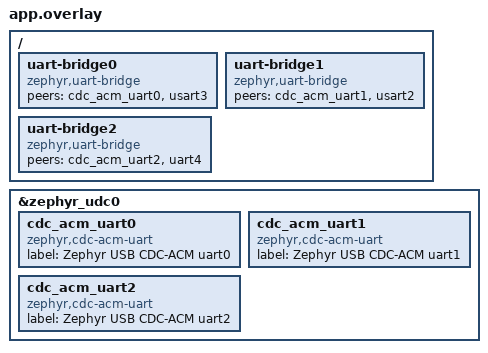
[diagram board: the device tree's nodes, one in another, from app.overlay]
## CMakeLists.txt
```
# SPDX-License-Identifier: Apache-2.0

cmake_minimum_required(VERSION 3.20.0)
find_package(Zephyr REQUIRED HINTS $ENV{ZEPHYR_BASE})
project(USB_UART_HUB)

include(${ZEPHYR_BASE}/samples/subsys/usb/common/common.cmake)
FILE(GLOB app_sources src/*.c)
target_sources(app PRIVATE ${app_sources})
```

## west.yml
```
manifest:
  remotes:
    - name: zephyrproject-rtos
      url-base: https://github.com/zephyrproject-rtos

  projects:
    - name: zephyr
      remote: zephyrproject-rtos
      revision: v4.3.0
      import:
        # Use the allow-list to keep it slim!
        name-allowlist:
          - cmsis
          - cmsis_6
          - hal_stm32

  self:
    path: USB_UART_HUB  # This matches your repo name
```

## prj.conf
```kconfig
CONFIG_UART_CONSOLE=y

CONFIG_USB_DEVICE_STACK_NEXT=y

CONFIG_SERIAL=y
CONFIG_UART_LINE_CTRL=y
CONFIG_UART_USE_RUNTIME_CONFIGURE=y
CONFIG_USBD_CDC_ACM_CLASS=y
CONFIG_CDC_ACM_SERIAL_INITIALIZE_AT_BOOT=n
CONFIG_UDC_BUF_POOL_SIZE=8192

CONFIG_SAMPLE_USBD_PID=0x0001
CONFIG_SAMPLE_USBD_PRODUCT="USBD CDC ACM bridge sample"

CONFIG_LOG=y
CONFIG_LOG_BUFFER_SIZE=8192

CONFIG_NET_BUF=y
# CONFIG_UART_ASYNC_API=y
CONFIG_UART_BRIDGE=y
```

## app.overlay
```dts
/*
 * Copyright 2025 Google LLC
 *
 * SPDX-License-Identifier: Apache-2.0
 */

/ {
	uart-bridge0 {
		compatible = "zephyr,uart-bridge";
		peers = <&cdc_acm_uart0 &usart3>;
	};

	uart-bridge1 {
		compatible = "zephyr,uart-bridge";
		peers = <&cdc_acm_uart1 &usart2>;
	};

	uart-bridge2 {
		compatible = "zephyr,uart-bridge";
		peers = <&cdc_acm_uart2 &uart4>;
	};
};


&zephyr_udc0 {
	cdc_acm_uart0: cdc_acm_uart0 {
		compatible = "zephyr,cdc-acm-uart";
		label = "Zephyr USB CDC-ACM uart0";
	};
	cdc_acm_uart1: cdc_acm_uart1 {
		compatible = "zephyr,cdc-acm-uart";
		label = "Zephyr USB CDC-ACM uart1";
	};
	cdc_acm_uart2: cdc_acm_uart2 {
		compatible = "zephyr,cdc-acm-uart";
		label = "Zephyr USB CDC-ACM uart2";
	};
};
```

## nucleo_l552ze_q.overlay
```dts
zephyr_udc0: &usb {
    pinctrl-0 = <&usb_dm_pa11 &usb_dp_pa12>;
    pinctrl-names = "default";
    status = "okay";
    cdc_acm_uart0 {
		compatible = "zephyr,cdc-acm-uart";
	};
};

&usart3 {
    pinctrl-0 = <&usart3_tx_pd8 &usart3_rx_pd9>;
    pinctrl-names = "default";
    status = "okay";
    label = "USART_3";
};

&usart2 {
    pinctrl-0 = <&usart2_tx_pd5 &usart2_rx_pd6>;
    pinctrl-names = "default";
    status = "okay";
    label = "USART_2";
};

&uart4 {
    pinctrl-0 = <&uart4_tx_pc10 &uart4_rx_pc11>;
    pinctrl-names = "default";
    status = "okay";
    label = "USART_2";
};
```

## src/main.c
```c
/*
 * Copyright 2025 Google LLC
 *
 * SPDX-License-Identifier: Apache-2.0
 */

#include <sample_usbd.h>

#include <stdio.h>
#include <string.h>
#include <zephyr/device.h>
#include <zephyr/drivers/uart/uart_bridge.h>
#include <zephyr/kernel.h>

#include <zephyr/usb/usb_device.h>
#include <zephyr/usb/usbd.h>
#include <zephyr/logging/log.h>
LOG_MODULE_REGISTER(USB_UART_HUB, LOG_LEVEL_INF);

const struct device *const uart_dev = DEVICE_DT_GET_ONE(zephyr_cdc_acm_uart);

static struct usbd_context *sample_usbd;

#define DEVICE_DT_GET_COMMA(node_id) DEVICE_DT_GET(node_id),

const struct device *uart_bridges[] = {
	DT_FOREACH_STATUS_OKAY(zephyr_uart_bridge, DEVICE_DT_GET_COMMA)
};

static void sample_msg_cb(struct usbd_context *const ctx, const struct usbd_msg *msg)
{
	LOG_INF("USBD message: %s", usbd_msg_type_string(msg->type));

	if (usbd_can_detect_vbus(ctx)) {
		if (msg->type == USBD_MSG_VBUS_READY) {
			if (usbd_enable(ctx)) {
				LOG_ERR("Failed to enable device support");
			}
		}

		if (msg->type == USBD_MSG_VBUS_REMOVED) {
			if (usbd_disable(ctx)) {
				LOG_ERR("Failed to disable device support");
			}
		}
	}

	if (msg->type == USBD_MSG_CDC_ACM_LINE_CODING ||
	    msg->type == USBD_MSG_CDC_ACM_CONTROL_LINE_STATE) {
		for (uint8_t i = 0; i < ARRAY_SIZE(uart_bridges); i++) {
			/* update all bridges, non valid combinations are
			 * skipped automatically.
			 */
			uart_bridge_settings_update(msg->dev, uart_bridges[i]);
		}
	}
}

int main(void)
{
	int err;
    LOG_INF("main starting");
    
	sample_usbd = sample_usbd_init_device(sample_msg_cb);
	if (sample_usbd == NULL) {
		LOG_ERR("Failed to initialize USB device");
		return -ENODEV;
	}

	if (!usbd_can_detect_vbus(sample_usbd)) {
		err = usbd_enable(sample_usbd);
		if (err) {
			LOG_ERR("Failed to enable device support");
			return err;
		}
	}

	LOG_INF("USB device support enabled");

	k_sleep(K_FOREVER);

	return 0;
}
```
